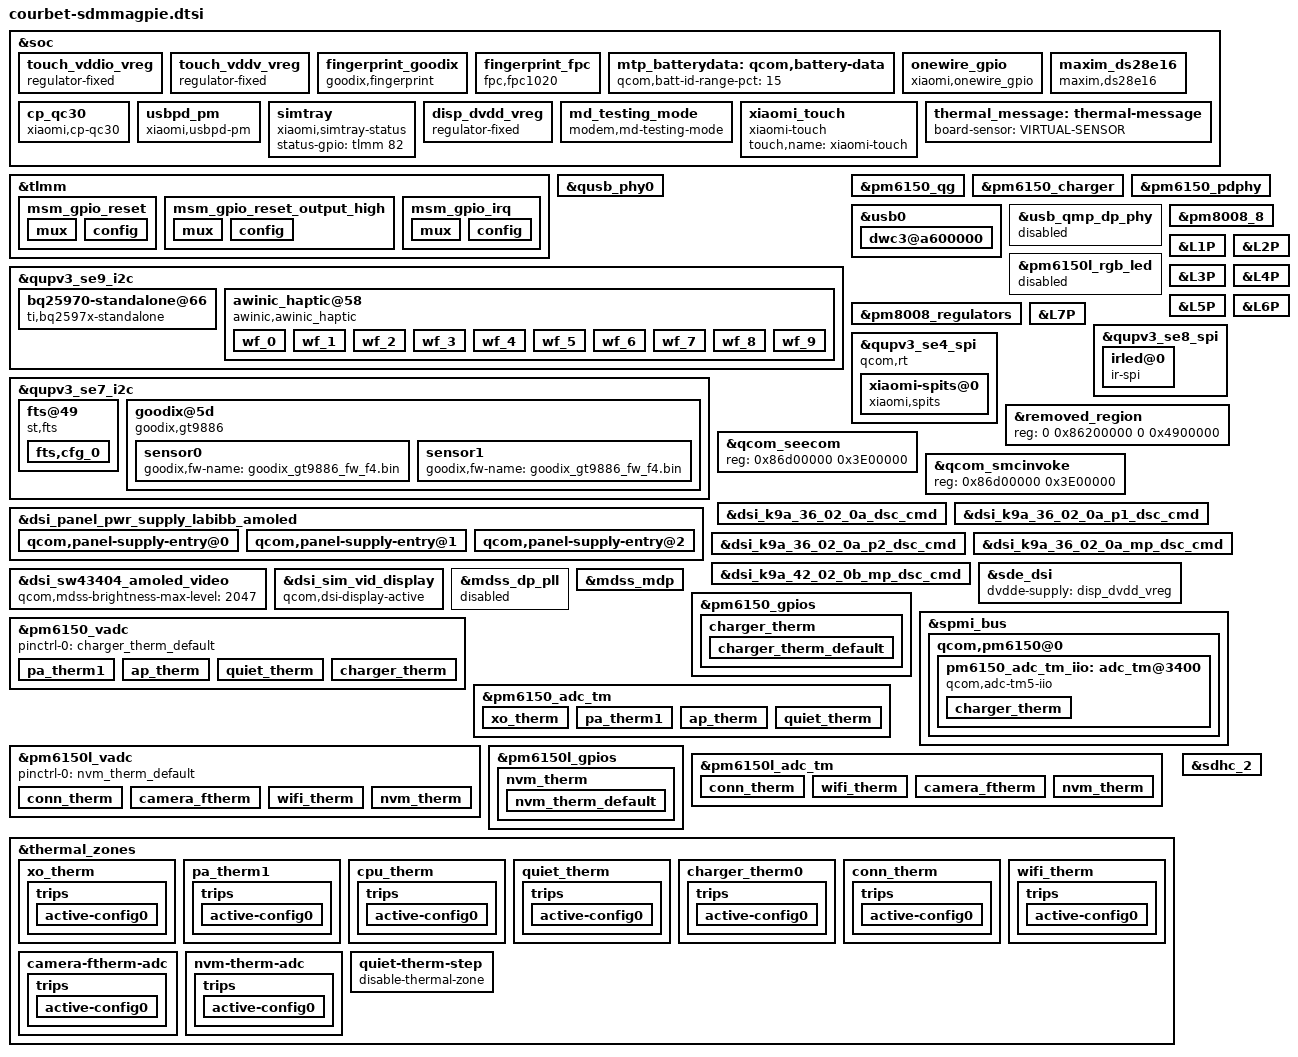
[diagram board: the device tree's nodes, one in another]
/*
this file is for attribution only of aquila
And public attribution of xiaomi platforms(like F3 and so and)
*/

#include "courbet-sdmmagpie-pinctrl.dtsi"
#include "xiaomi-sdmmagpie-common.dtsi"
#include "courbet-sdmmagpie-camera-sensor.dtsi"
&soc {
	touch_vddio_vreg: touch_vddio_vreg {
		compatible = "regulator-fixed";
		regulator-name = "disp_vddio_vreg";
		startup-delay-us = <4000>;
		enable-active-high;
		regulator-boot-off;
		gpio = <&tlmm 72 0>;
		status = "ok";
	};

	touch_vddv_vreg: touch_vddv_vreg {
		compatible = "regulator-fixed";
		regulator-name = "disp_vddio_vreg";
		startup-delay-us = <4000>;
		enable-active-high;
		regulator-boot-off;
		gpio = <&tlmm 21 0>;
		status = "ok";
	};
	fingerprint_goodix {
		compatible = "goodix,fingerprint";
		goodix,gpio-reset = <&tlmm 65 0x0>;
		goodix,gpio-irq = <&tlmm 91 0x0>;
		fp-gpio-pwr = <&tlmm 63 0>;
		status = "ok";
	};

	fingerprint_fpc {
		status = "ok";
		compatible = "fpc,fpc1020";
		interrupt-parent = <&tlmm>;
		interrupts = <91 0x0>;
		fpc,gpio_rst    = <&tlmm 65 0x0>;
		fpc,gpio_irq    = <&tlmm 91 0x0>;
		fpc,gpio_vdd1v8 = <&tlmm 63  0x0>;
		pinctrl-names = "fpc1020_reset_reset",
				"fpc1020_reset_active",
				"fpc1020_irq_active";

		pinctrl-0 = <&msm_gpio_reset>;
		pinctrl-1 = <&msm_gpio_reset_output_high>;
		pinctrl-2 = <&msm_gpio_irq>;
	};


	mtp_batterydata: qcom,battery-data {
		qcom,batt-id-range-pct = <15>;
		#include "qg-batterydata-K9A-cosmx-4250mah.dtsi"
		#include "qg-batterydata-K9A-sunwoda-4250mah.dtsi"
	};

	onewire_gpio: onewire_gpio{
		compatible = "xiaomi,onewire_gpio";
		label = "xm_onewire";
		xiaomi,version = <1>;
		xiaomi,ow_gpio = <&tlmm 94 0x00>;
		mi,onewire-gpio-cfg-addr = <0x03D5E000 0x4>;
		pinctrl-names = "onewire_active", "onewire_sleep";
		pinctrl-0 = <&onewire_gpio_active>;
		pinctrl-1 = <&onewire_gpio_sleep>;
		status = "ok";
	};

	maxim_ds28e16: maxim_ds28e16{
		compatible = "maxim,ds28e16";
		label = "max_ds28e16";
		maxim,version = <1>;
		status = "ok";
	};

	cp_qc30 {
		compatible = "xiaomi,cp-qc30";
		status = "ok";
		mi,qc3-bat-volt-max = <4450>;
		mi,qc3-ffc-bat-volt-max = <4470>;
		mi,qc3-bat-curr-max = <5400>;
		mi,qc3-bus-volt-max = <12000>;
		mi,qc3-bus-curr-max = <2100>;
		mi,support-qc3p5-without-smb;
	};

	usbpd_pm {
		compatible = "xiaomi,usbpd-pm";
		status = "ok";
		mi,pd-bat-volt-max = <4450>;
		mi,pd-ffc-bat-volt-max = <4470>;
		mi,pd-bat-curr-max = <6000>;
		mi,pd-bus-volt-max = <12000>;
		mi,pd-bus-curr-max = <3000>;
		mi,pd-bus-curr-compensate = <200>;
		mi,disable-taper-fcc;
	};

	simtray {
		compatible = "xiaomi,simtray-status";
		status-gpio = <&tlmm 82 0x00>;
	};

	disp_dvdd_vreg: disp_dvdd_vreg {
		compatible = "regulator-fixed";
		regulator-name = "disp_dvdd_vreg";
		startup-delay-us = <4000>;
		enable-active-high;
		regulator-boot-off;
		gpio = <&tlmm 30 0>;
	};

	md_testing_mode {
		compatible = "modem,md-testing-mode";
		status-gpio = <&tlmm 57 0x00>;
		debounce-time = <30>;
		pinctrl-names = "default";
		pinctrl-0 = <&test_mode_irq>;
	};
};

&tlmm {
	/* FP_RESET_N */
	msm_gpio_reset: msm_gpio_reset {
		mux {
			pins = "gpio65";
			function = "gpio";
		};
		config {
			pins = "gpio65";
			drive-strength = <2>;
			bias-disable;
			output-low;
		};
	};
	/* FP_RESET_N, state device active*/
	msm_gpio_reset_output_high: msm_gpio_reset_output_high {
		mux {
			pins = "gpio65";
			function = "gpio";
		};
		config {
			pins = "gpio65";
			drive-strength = <2>;
			bias-disable;
			output-high;
		};
	};
	/* FP_INT_N */
	msm_gpio_irq: msm_gpio_irq {
		mux {
			pins = "gpio91";
			function = "gpio";
		};
		config {
			pins = "gpio91";
			drive-strength = <2>;
			bias-pull-down;
		};
	};
};


&qusb_phy0 {
	mi,no-efuse-tune;

	qcom,qusb-phy-init-seq =
		/* <value reg_offset> */
		<0x23 0x210 /* PWR_CTRL1 */
		0x03 0x04  /* PLL_ANALOG_CONTROLS_TWO */
		0x7c 0x18c /* PLL_CLOCK_INVERTERS */
		0x80 0x2c  /* PLL_CMODE */
		0x0a 0x184 /* PLL_LOCK_DELAY */
		0x19 0xb4  /* PLL_DIGITAL_TIMERS_TWO */
		0x40 0x194 /* PLL_BIAS_CONTROL_1 */
		0x18 0x198 /* PLL_BIAS_CONTROL_2 */
		0x21 0x214 /* PWR_CTRL2 */
		0x08 0x220 /* IMP_CTRL1 */
		0x58 0x224 /* IMP_CTRL2 */
		0x47 0x240 /* TUNE1 */
		0x2b 0x244 /* TUNE2 */
		0xca 0x248 /* TUNE3 */
		0x02 0x24c /* TUNE4 */
		0x03 0x250 /* TUNE5 */
		0x30 0x23c /* CHG_CTRL2 */
		0x22 0x210>; /* PWR_CTRL1 */

	qcom,qusb-phy-host-init-seq =
		/* <value reg_offset> */
		<0x23 0x210 /* PWR_CTRL1 */
		0x03 0x04  /* PLL_ANALOG_CONTROLS_TWO */
		0x7c 0x18c /* PLL_CLOCK_INVERTERS */
		0x80 0x2c  /* PLL_CMODE */
		0x0a 0x184 /* PLL_LOCK_DELAY */
		0x19 0xb4  /* PLL_DIGITAL_TIMERS_TWO */
		0x40 0x194 /* PLL_BIAS_CONTROL_1 */
		0x18 0x198 /* PLL_BIAS_CONTROL_2 */
		0x21 0x214 /* PWR_CTRL2 */
		0x08 0x220 /* IMP_CTRL1 */
		0x58 0x224 /* IMP_CTRL2 */
		0x47 0x240 /* TUNE1 */
		0x2b 0x244 /* TUNE2 */
		0xca 0x248 /* TUNE3 */
		0x02 0x24c /* TUNE4 */
		0x03 0x250 /* TUNE5 */
		0x30 0x23c /* CHG_CTRL2 */
		0x22 0x210>; /* PWR_CTRL1 */
};

&qupv3_se9_i2c {
	status = "ok";
	qcom,clk-freq-out = <400000>;
	qcom,clk-freq-in = <400000>;

	bq25970-standalone@66 {
		compatible = "ti,bq2597x-standalone";
		reg = <0x66>;

		interrupt-parent = <&tlmm>;
		interrupts = <58 0x2002>;
		pinctrl-names = "default";
		pinctrl-0 = <&bq2597x_int_default &bq2597x_int_suspend>;

		mp-sc-vbat-calibrate = <(-10000)>;
		pre-mp-sc-vbat-calibrate = <(-20000)>;
		ti-vbat-calibrate = <(-10000)>;

		//ti,bq2597x,bat-ovp-disable;
		ti,bq2597x,bat-ovp-alarm-disable;
		ti,bq2597x,bat-ocp-disable;
		ti,bq2597x,bat-ocp-alarm-disable;
		ti,bq2597x,bat-ucp-alarm-disable;
		ti,bq2597x,bat-ucp-disable;

		//ti,bq2597x,bus-ovp-alarm-disable;
		//ti,bq2597x,bus-ocp-disable;
		//ti,bq2597x,bus-ocp-alarm-disable;
		ti,bq2597x,bat-therm-disable;
		ti,bq2597x,bus-therm-disable;
		ti,bq2597x,die-therm-disable;

		ti,bq2597x,bat-ovp-threshold = <4525>;
		ti,bq2597x,bat-ovp-alarm-threshold = <4500>;
		//ti,bq2597x,bat-ocp-threshold = <5000>;
		//ti,bq2597x,bat-ocp-alarm-threshold = <4500>;

		ti,bq2597x,bus-ovp-threshold = <12000>;
		ti,bq2597x,bus-ovp-alarm-threshold = <11000>;
		//ti,bq2597x,bus-ocp-threshold = <2200>;
		//ti,bq2597x,bus-ocp-alarm-threshold = <2000>;
		ti,bq2597x,bus-ocp-threshold = <3500>;
		ti,bq2597x,bus-ocp-alarm-threshold = <3200>;

		//ti,bq2597x,bat-ucp-alarm-threshold = <2000>;

		ti,bq2597x,bat-therm-threshold = <0x15>;/*4.1%*/
		ti,bq2597x,bus-therm-threshold = <0x15>;/*4.1%*/
		ti,bq2597x,die-therm-threshold = <145>;

		ti,bq2597x,ac-ovp-threshold = <14>;
		//ti,bq2597x,sense-resistor-mohm = <2>;

		//sc8551,bypass-enable;
	};

	awinic_haptic@58 {
		compatible = "awinic,awinic_haptic";
		reg = <0x5A>;
		aw8622x_i2c_addr = < 0x58 >;
		reset-gpio = <&tlmm 4 0>;
		irq-gpio = <&pm6150l_gpios  10 0>;
		pinctrl-names = "awinic_reset_reset","awinic_reset_active","awinic_interrupt_active";
		pinctrl-0 = <&awinic_gpio_reset>;
		pinctrl-1 = <&awinic_gpio_reset_output_high>;
		pinctrl-2 = <&awinic_gpio_int>;
		/*---------------------aw8624_dts_info---------------------*/
		aw8624_vib_f0_pre = < 2050 >;
		aw8624_vib_f0_cali_percen = < 7 >;
		aw8624_vib_cont_drv_lev = < 106 >;
		aw8624_vib_cont_drv_lvl_ov = < 155 >;
		aw8624_vib_cont_td = < 0xF06C >;
		aw8624_vib_cont_zc_thr = < 0x08F8 >;
		aw8624_vib_cont_num_brk = < 3 >;
		aw8624_vib_f0_coeff = < 260 >; /*Don't modify it*/
		aw8624_vib_duration_time = < 15 60 0 0 0 >;
		aw8624_vib_brake_ram_config = < 1 1 90 60 20 3 1 3 1 1 90 60 30 5 1 3 0 0 50 40 25 0 5 3 >;
		aw8624_vib_brake_cont_config = < 1 1 90 42 20 5 2 2 0 0 0 0 0 0 0 0 0 0 0 0 0 0 0 0 >;
		aw8624_vib_f0_trace_parameter = < 9 5 1 15 >;
		aw8624_vib_bemf_config = < 0 8 3 0xf8 >;
		aw8624_vib_sw_brake = < 0x2c >;
		aw8624_vib_wavseq = < 0 1 1 2 0 0 0 0 0 0 0 0 0 0 0 0 >; /*wavseq1-seq8 0x07-0x0E*/
		aw8624_vib_wavloop = < 0 6 1 15 0 0 0 0 0 0>;/*loop1-mainloog 0x0f-0x13*/
		aw8624_vib_td_brake = < 42720 42720 42720 >; /*level0 level1 level2*/
		aw8624_vib_tset = < 0x11 >;
		aw8624_vib_func_parameter1 = < 1 >;
		aw8624_vib_gain_flag = < 1 >;
		aw8624_vib_r_spare = < 0x68 >;
		aw8624_vib_bstdbg = < 0x30 0xeb 0xd4 0 0 0 >;
		/*---------------------aw8622x_dts_info---------------------*/
		aw8622x_vib_mode = < 0 >; /* mode: RAM mode->0; CONT mode->1 */
		aw8622x_vib_f0_pre = < 2050 >;
		aw8622x_vib_f0_cali_percen = < 7 >;
		aw8622x_vib_cont_drv1_lvl = < 0x7F >;
		aw8622x_vib_cont_drv2_lvl = < 0x3A >;
		aw8622x_vib_cont_brk_time = < 0x06 >;
		aw8622x_vib_cont_tset = < 0x06 >;
		aw8622x_vib_cont_bemf_set = < 0x02 >;
		aw8622x_vib_cont_drv_width = < 0x56 >;
		aw8622x_vib_cont_wait_num = < 0x06 >;
		aw8622x_vib_cont_brk_gain = < 0x08 >;
		aw8622x_vib_cont_drv1_time = < 0x08 >;
		aw8622x_vib_cont_drv2_time = < 0x14 >;
		aw8622x_vib_cont_track_margin = < 0x0F >;
		aw8622x_vib_sine_array = < 0x05 0xB2 0xFF 0xEF >; /* SIN_H SIN_L COS_H COS_L*/
		aw8622x_vib_d2s_gain = < 0x05 >;
		aw8622x_vib_prctmode = < 0x2D 0x3E 0x3F >;
		/*---------------------common_dts_info---------------------*/
		vib_effect_id_boundary = < 10 >;
		vib_effect_max = < 170 >;
		vib_rtp_time = < 20 20 20 20 20 20 20 20 20 30
				 40 50 60 70 80 90 100 110 120 130
				 140 150 160 170 180 190 200 210 220 230
				 240 250 260 270 280 290 300 310 320 330
				 20 20 20 20 20 20 20 20 20 20
				 20 20 20 20 20 20 20 20 20 20
				 20 20 20 20 20 20 20 20 20 20
				 20 20 20 20 20 20 20 20 20 20
				 20 20 20 20 20 20 20 20 20 20
				 20 20 20 20 20 20 20 20 20 20
				 20 20 20 20 20 20 20 20 20 20
				 20 20 20 20 20 20 20 20 20 20
				 20 20 20 20 20 20 20 20 20 20
				 20 20 20 20 20 20 20 20 20 20
				 20 20 20 20 20 20 20 20 20 20
				 20 20 20 20 20 20 20 20 20 20
				 20 20 20 20 20 20 20 20 20 20
				 20 20 20 20 20 >;
		status = "okay";
		wf_0 {
			/*CLICK*/
			qcom,effect-id = <0>;
			qcom,wf-vmax-mv = <3600>;
			qcom,wf-pattern = [3e 3e];
			qcom,wf-brake-pattern = [02 01 00 00];
			qcom,wf-play-rate-us = <20000>;
		};
		wf_1 {
			/*DOUBLE CLICK*/
			qcom,effect-id = <1>;
			qcom,wf-vmax-mv = <3600>;
			qcom,wf-pattern = [7e 3e];
			qcom,wf-brake-pattern = [03 01 00 00];
			qcom,wf-play-rate-us = <20000>;
		};
		wf_2 {
			/*TICK*/
			qcom,effect-id = <2>;
			qcom,wf-vmax-mv = <3600>;
			qcom,wf-pattern = [7e 3e];
			qcom,wf-brake-pattern = [02 01 00 00];
			qcom,wf-play-rate-us = <20000>;
		};
		wf_3 {
			/*THUD*/
			qcom,effect-id = <3>;
			qcom,wf-vmax-mv = <3600>;
			qcom,wf-pattern = [3e 3e];
			qcom,wf-brake-pattern = [02 01 00 00];
			qcom,wf-play-rate-us = <20000>;
		};
		wf_4 {
			/*POP*/
			qcom,effect-id = <4>;
			qcom,wf-vmax-mv = <3600>;
			qcom,wf-pattern = [3e 3e];
			qcom,wf-brake-pattern = [02 01 00 00];
			qcom,wf-play-rate-us = <28000>;
		};
		wf_5 {
			/*HEAVY CLICK*/
			qcom,effect-id = <5>;
			qcom,wf-vmax-mv = <3600>;
			qcom,wf-pattern = [7e 7e 7e];
			qcom,wf-brake-pattern = [03 03 01 00];
			qcom,wf-play-rate-us = <20000>;
		};
		wf_6 {
			/*id 6*/
			qcom,effect-id = <6>;
			qcom,wf-vmax-mv = <3600>;
			qcom,wf-pattern = [3e 3e];
			qcom,wf-brake-pattern = [02 01 00 00];
			qcom,wf-play-rate-us = <20000>;
		};
		wf_7 {
			/*id 7*/
			qcom,effect-id = <7>;
			qcom,wf-vmax-mv = <3600>;
			qcom,wf-pattern = [3e 3e];
			qcom,wf-brake-pattern = [02 01 00 00];
			qcom,wf-play-rate-us = <20000>;
		};
		wf_8 {
			/*id 8*/
			qcom,effect-id = <8>;
			qcom,wf-vmax-mv = <3600>;
			qcom,wf-pattern = [3e 3e];
			qcom,wf-brake-pattern = [02 01 00 00];
			qcom,wf-play-rate-us = <20000>;
		};
		wf_9 {
			/*id 9*/
			qcom,effect-id = <9>;
			qcom,wf-vmax-mv = <3600>;
			qcom,wf-pattern = [3e 3e];
			qcom,wf-brake-pattern = [02 01 00 00];
			qcom,wf-play-rate-us = <20000>;
		};
	};
	/* AWINIC AW8624 Haptic End */
};

&pm6150_qg {
	qcom,battery-data = <&mtp_batterydata>;
	qcom,vbatt-cutoff-mv = <3400>;
	qcom,vbatt-low-mv = <3500>;
	qcom,vbatt-low-cold-mv = <3800>;
	qcom,vbatt-empty-mv = <3100>;
	qcom,vbatt-empty-cold-mv = <3000>;
	qcom,s3-entry-fifo-length = <2>;
	qcom,s3-entry-ibat-ua = <25000>;
	qcom,s3-exit-ibat-ua = <45000>;
	qcom,qg-iterm-ma = <300>;
	qcom,hold-soc-while-full;
	qcom,linearize-soc;
	qcom,cl-feedback-on;
	qcom,shutdown-soc-threshold = <10>;
	qcom,qg-ext-sns;
	mi,software-optimize-ffc-qg-iterm;
	qcom,shutdown-delay-enable;
	qcom,tcss-enable;
	qcom,tcss-entry-soc = <90>;
	qcom,bass-enable;
	qcom,disable-hold-full;

	qcom,soc_decimal_rate = <
		0  32
		10 30
		20 28
		30 28
		40 28
		50 28
		60 28
		70 28
		80 28
		90 26
		95 10
		99 5>;
};

&pm6150_charger {
	io-channels = <&pm6150_vadc ADC_USB_IN_V_16>,
		      <&pm6150_vadc ADC_USB_IN_I>,
		      <&pm6150_vadc ADC_CHG_TEMP>,
		      <&pm6150_vadc ADC_DIE_TEMP>,
		      <&pm6150l_vadc ADC_AMUX_THM1_PU2>,
		      <&pm6150_vadc ADC_SBUx>,
		      <&pm6150_vadc ADC_VPH_PWR>;
	io-channel-names = "usb_in_voltage",
			   "usb_in_current",
			   "chg_temp",
			   "die_temp",
			   "conn_temp",
			   "sbux_res",
			   "vph_voltage";
	qcom,battery-data = <&mtp_batterydata>;
	qcom,usb-icl-ua = <3000000>;
	mi,ffc-low-tbat = <150>;
	mi,ffc-high-tbat = <480>;
	qcom,fcc-max-ua = <6000000>;
	mi,fcc-batt-unverify-ua = <2000000>;
	qcom,fv-max-uv = <4480000>;
	qcom,auto-recharge-soc = <99>;
	qcom,chg-term-src = <1>;
	qcom,chg-term-current-ma = <(-200)>;
	qcom,sec-charger-config = <0>;

	qcom,thermal-mitigation = <5900000 5000000 4500000 4000000 3500000 3000000 2900000
				   2800000 2600000 2400000 2200000 2000000 1800000 1500000
				   1000000 500000>;
	qcom,thermal-mitigation-icl
				 = <3000000 3000000 3000000 2400000 2200000 2100000 2000000
				   2000000 2000000 1900000 1800000 1600000 1500000 1300000
				   1000000 750000>;
	qcom,thermal-mitigation-dcp
				= <1800000 1800000 1800000 1800000 1800000 1800000 1800000
				   1800000 1800000 1700000 1600000 1400000 1200000 1100000
				   1100000 1000000>;
	qcom,thermal-mitigation-qc2
				= <1500000 1500000 1500000 1500000 1450000 1400000 1350000
				   1300000 1150000 1100000 1000000 900000 850000 750000
				   650000 500000>;
	qcom,thermal-fcc-qc3-normal
				= <6000000 5000000 4500000 4000000 3500000 3000000 2900000
				   2800000 2700000 2600000 2400000 2200000 2000000 2000000
				   750000 700000>;
	qcom,thermal-fcc-qc3-cp
				= <6000000 5000000 4500000 4000000 3500000 3300000 3200000
				   3100000 3000000 2800000 2600000 2400000 2200000 2000000
				   2000000 200000>;
	qcom,thermal-mitigation-pd-base
				= <6000000 5000000 4500000 4000000 3400000 3300000 3200000
				   3100000 3000000 2800000 2600000 2400000 2200000 2000000
				   1000000 700000>;
	qcom,thermal-fcc-pps-cp
				= <6000000 5700000 5400000 5000000 4700000 4400000 4100000
				   3800000 3500000 3200000 2800000 2400000 2000000 1500000
				   1000000 700000>;
	dpdm-supply = <&qusb_phy0>;
	qcom,reg-dump-enable;
	qcom,sw-jeita-enable;
	qcom,step-charging-enable;
	qcom,distinguish-qc-class-ab;
	qcom,lpd-disable;
	qcom,usbpd-phandle = <&pm6150_pdphy>;
	qcom,support-conn-therm;
	qcom,disable-suspend-on-collapse;

	mi,use-bq-pump;
	mi,support-ffc;
	mi,early-status-report;
	mi,support-qc3p5-without-smb;
	mi,pps-thermal-setting-disable;
	mi,fcc-calibrate-ua = <(-50000)>;
	mi,reverse_boost-wa;
	mi,rara-cc2-toggle-wa;

	uart-en-gpio = <&tlmm 33 0>;
	pinctrl-names = "default";
	pinctrl-0 = <&uart_en_default>;
};

&pm6150_pdphy {
	mi,non-qcom-pps-ctrl;
	mi,pd_curr_limit = <1>;
	mi,pd_max_curr_limit = <4000000>;
	mi,limit_pd_unverified_pps_vbus = <1>;
	mi,pd_unverified_pps_max_vbus_limit = <9500000>;
	mi,smart-interchg-enable;
};

&usb0 {
	dwc3@a600000 {
		usb-phy = <&qusb_phy0>, <&usb_nop_phy>;
		maximum-speed = "high-speed";
	};
};

&usb_qmp_dp_phy {
	status = "disabled";
};


&pm6150l_rgb_led {
	status = "disabled";
};


&qupv3_se7_i2c{
	status = "ok";
	fts@49 {
		compatible = "st,fts";
		reg = <0x49>;
		interrupt-parent = <&tlmm>;
		interrupts = <9 0x2008>;
		pinctrl-names = "pmx_ts_active", "pmx_ts_suspend";
		pinctrl-0 = <&ts_active>;
		pinctrl-1 = <&ts_int_suspend &ts_reset_suspend>;
		vdd-supply = <&touch_vddio_vreg>;
		avdd-supply = <&pm6150l_l6>;
		fts,pwr-reg-name = "avdd";
		fts,bus-reg-name = "vdd";
		fts,irq-gpio = <&tlmm 9 0x2008>;
		fts,irq-gpio-name = "fts_irq";
		fts,reset-gpio-enable;
		fts,reset-gpio = <&tlmm 8 0x00>;
		fts,reset-gpio-name = "fts_rst";
		fts,irq-flags = <0x2008>; /* IRQF_ONESHOT | IRQF_TRIGGER_LOW */
		fts,x-max = <1080>;
		fts,y-max = <2340>;
		fts,default-fw-name = "st_fts_f4l.ftb";
		fts,config-array-size = <1>;
		fts,dump-click-count;
		fts,touch-up-threshold-min = <40>;
		fts,touch-up-threshold-max = <120>;
		fts,touch-up-threshold-def = <80>;
		fts,touch-tolerance-min = <5>;
		fts,touch-tolerance-max = <35>;
		fts,touch-tolerance-def = <25>;
		/*edge filter rects in gamemode*/
		fts,cornerfilter-area-step1 = <100>;
		fts,cornerfilter-area-step2 = <170>;
		fts,cornerfilter-area-step3 = <250>;
		fts,touch-deadzone-filter-ver = <2 0 0 0 0 0 0 0
									    2 1 0 0 0 0 0 0
									    2 2 0 0 5 2339 0 0
									    2 3 1074 0 1079 2339 0 0>;
		fts,touch-deadzone-filter-hor = <2 0 0 0 1079 5 0 0
									    2 1 0 2334 1079 2339 0 0
									    2 2 0 0 5 2339 0 0
									    2 3 1074 0 1079 2339 0 0>;
		fts,touch-edgezone-filter-ver = <1 0 0 0 0 0 0 0
									    1 1 0 0 0 0 0 0
									    1 2 0 0 40 2339 0 0
									    1 3 1039 0 1079 2339 0 0>;
		fts,touch-edgezone-filter-hor = <1 0 0 0 1079 40 0 0
									    1 1 0 2299 1079 2339 0 0
									    1 2 0 0 40 2339 0 0
									    1 3 1039 0 1079 2339 0 0>;
		fts,touch-cornerzone-filter-ver = <0 0 0 0 0 0 0 0
									    0 1 0 0 0 0 0 0
									    0 2 0 2039 150 2339 0 0
									    0 3 929 2039 1079 2339 0 0>;
		fts,touch-cornerzone-filter-hor1 = <0 0 0 0 170 170 0 0
									    0 1 0 0 0 0 0 0
									    0 2 0 2169 170 2339 0 0
									    0 3 0 0 0 0 0 0>;
		fts,touch-cornerzone-filter-hor2 = <0 0 0 0 0 0 0 0
									    0 1 909 0 1079 170 0 0
									    0 2 0 0 0 0 0 0
									    0 3 909 2169 1079 2339 0 0>;
		fts,touch-idletime-min = <0>;
		fts,touch-idletime-max = <12750>;
		fts,touch-idletime-def = <12450>;
		fts,cfg_0 {
			fts,tp-vendor = <0x51>;
			fts,fw-name = "st_fts_f4l.ftb";
			fts,limit-name = "stm_fts_production_limits.csv";
			fts,clicknum-file-name = "fts+sdc";
		};
	};
	goodix@5d {
		compatible = "goodix,gt9886";
		reg = <0x5d>;
		status = "ok";
		interrupt-parent = <&tlmm>;
		interrupts = <9 0x2800>;
		vtouch-supply = <&pm6150l_l6>;
		iotouch-supply = <&touch_vddio_vreg>;
		vtouch-load = <600000>;
		pinctrl-names = "pmx_ts_active","pmx_ts_suspend";
		pinctrl-0 = <&tp_active>;
		pinctrl-1 = <&tp_int_suspend &tp_reset_suspend>;
		goodix,reset-gpio = <&tlmm 8 0x0>;
		goodix,irq-gpio = <&tlmm 9 0x2800>;
		goodix,irq-flags = <2>; /* 1:trigger rising, 2:trigger falling;*/
		goodix,panel-max-id = <10>;
		goodix,panel-max-x = <1079>;
		goodix,panel-max-y = <2339>;
		goodix,panel-max-w = <127>;
		goodix,panel-max-p = <127>;
		goodix,panel-max-fod = <127>;
	/*	goodix,panel-key-map = <158 172 217>; */ /*KEY_BACK, KEY_HOMEPAGE, KEY_SEARCH*/
		goodix,power-on-delay-us = <300000>; /*300ms*/
		goodix,power-off-delay-us = <5000>;
		goodix,cfg-name = "goodix_gt9886_cfg_f4.bin";
		normal-cfg = [
				];
	/*	goodix,swap-axis; */
	/*	goodix,pen-enable; */
	/*	goodix,key-of-pen = <331 332>; */ /*BTN_STYLUS, BTN_STYLUS2*/
		goodix,touch-deadzone-filter-ver = <2 0 0 0 0 0 0 0
									    2 1 0 0 0 0 0 0
									    2 2 0 0 5 2339 0 0
									    2 3 1074 0 1079 2339 0 0>;
		goodix,touch-deadzone-filter-hor = <2 0 0 0 1079 5 0 0
									    2 1 0 2334 1079 2339 0 0
									    2 2 0 0 5 2339 0 0
									    2 3 1074 0 1079 2339 0 0>;
		goodix,touch-edgezone-filter-ver = <1 0 0 0 0 0 0 0
									    1 1 0 0 0 0 0 0
									    1 2 0 0 40 2339 0 0
									    1 3 1039 0 1079 2339 0 0>;
		goodix,touch-edgezone-filter-hor = <1 0 0 0 1079 40 0 0
									    1 1 0 2299 1079 2339 0 0
									    1 2 0 0 40 2339 0 0
									    1 3 1039 0 1079 2339 0 0>;
		goodix,touch-cornerzone-filter-ver = <0 0 0 0 0 0 0 0
									    0 1 0 0 0 0 0 0
									    0 2 0 2039 150 2339 0 0
									    0 3 929 2039 1079 2339 0 0>;
		goodix,touch-cornerzone-filter-hor1 = <0 0 0 0 170 170 0 0
									    0 1 0 0 0 0 0 0
									    0 2 0 2169 170 2339 0 0
									    0 3 0 0 0 0 0 0>;
		goodix,touch-cornerzone-filter-hor2 = <0 0 0 0 0 0 0 0
									    0 1 909 0 1079 170 0 0
									    0 2 0 0 0 0 0 0
									    0 3 909 2169 1079 2339 0 0>;
		goodix,edge-filter-corner-size = /bits/ 16 <100 170 250>;
		sensor0 {
				goodix,fw-name = "goodix_gt9886_fw_f4.bin";
				/*goodix,x2x;*/
				/*goodix,y2y;*/
		};
		sensor1 {
				goodix,fw-name = "goodix_gt9886_fw_f4.bin";
		};
	};
        #include "pm8008.dtsi"
};

&pm8008_8 {
	/* PM8008 IRQ STAT */
	interrupt-parent = <&tlmm>;
	interrupts = <93 IRQ_TYPE_EDGE_RISING>;

	pinctrl-names = "default";
	pinctrl-0 = <&pm8008_active &pm8008_interrupt>;
};

&pm8008_regulators {
	vdd_l1_l2-supply = <&S8C>;
	vdd_l3_l4-supply = <&BOB>;
	vdd_l5-supply = <&S5A>;
	vdd_l6-supply = <&BOB>;
	vdd_l7-supply = <&BOB>;
};

&L1P {
	regulator-max-microvolt = <1050000>;
	qcom,min-dropout-voltage = <192000>;
};

&L2P {
	regulator-max-microvolt = <1200000>;
	qcom,min-dropout-voltage = <192000>;
};

&L3P {
	regulator-max-microvolt = <2800000>;
	qcom,min-dropout-voltage = <128000>;
};

&L4P {
	regulator-max-microvolt = <2804000>;
	qcom,min-dropout-voltage = <96000>;
};

&L5P {
	regulator-max-microvolt = <1800000>;
	qcom,min-dropout-voltage = <200000>;
};

&L6P {
	regulator-max-microvolt = <2800000>;
	/* Reduced the headroom by 16mV for AHC */
	qcom,min-dropout-voltage = <56000>;
};

&L7P {
	regulator-max-microvolt = <2700000>;
	qcom,min-dropout-voltage = <120000>;
};

&qupv3_se8_spi {
	status = "ok";
	irled@0 {
		compatible = "ir-spi";
		reg = <0x0>;
		status = "ok";
		spi-max-frequency = <19200000>;
	};
};

&qupv3_se4_spi {
	status = "ok";
	qcom,rt;

	xiaomi-spits@0 {
		status = "ok";
		compatible = "xiaomi,spits";
		reg = <0>;
		spi-max-frequency = <8000000>;
		goodix,avdd-name = "avdd";
		avdd-supply = <&touch_vddv_vreg>;
		goodix,pmavdd-name = "pmavdd";
		pmavdd-supply = <&pm6150l_l11>;
		goodix,iovdd-name = "iovdd";
		iovdd-supply = <&touch_vddio_vreg>;
		goodix,reset-gpio = <&tlmm 8 0x0>;
		goodix,irq-gpio = <&tlmm 9 0x2800>;
		goodix,irq-flags = <2>; /* 1:trigger rising, 2:trigger falling;*/
		goodix,panel-max-x = <1079>;
		goodix,panel-max-y = <2399>;
		goodix,panel-max-w = <255>;
		goodix,panel-max-p = <255>; /* max pressure that pen device supported */
		/* goodix,pen-enable; */ /* support active stylus device*/

		pinctrl-names = "pmx_ts_active", "pmx_ts_suspend", "pmx_ts_release";
		pinctrl-0 = <&ts_active>;
		pinctrl-1 = <&ts_int_suspend &ts_reset_suspend>;
		pinctrl-2 = <&ts_release>;
		vdd-supply = <&pm6150l_l11>;
		vcc_i2c-supply = <&touch_vddio_vreg>;
		focaltech,reset-gpio = <&tlmm 8 0x00>;
		focaltech,irq-gpio = <&tlmm 9 0x2008>;
		focaltech,max-touch-number = <10>;
		focaltech,display-coords = <0 0 1080 2400>;
	};
};

&soc {
	xiaomi_touch {
		compatible = "xiaomi-touch";
		status = "ok";
		touch,name = "xiaomi-touch";
	};
	thermal_message: thermal-message {
		board-sensor = "VIRTUAL-SENSOR";
	};
};

/* Enlarge TZ memory size to 62M */
&removed_region {
	reg = <0 0x86200000 0 0x4900000>;
};

&qcom_seecom {
	reg = <0x86d00000 0x3E00000>;
};

&qcom_smcinvoke {
	reg = <0x86d00000 0x3E00000>;
};


&dsi_panel_pwr_supply_labibb_amoled {

	qcom,panel-supply-entry@0 {
		reg = <0>;
		qcom,supply-name = "vddio";
		qcom,supply-min-voltage = <1880000>;
		qcom,supply-max-voltage = <1880000>;
		qcom,supply-enable-load = <32000>;
		qcom,supply-disable-load = <80>;
		qcom,supply-pre-off-sleep = <20>;
		qcom,supply-post-off-sleep = <100>;
	};

	qcom,panel-supply-entry@1 {
		reg = <1>;
		qcom,supply-name = "dvdde";
		qcom,supply-min-voltage = <1200000>;
		qcom,supply-max-voltage = <1200000>;
		qcom,supply-enable-load = <32000>;
		qcom,supply-disable-load = <80>;
		qcom,supply-pre-off-sleep = <10>;
	};

	qcom,panel-supply-entry@2 {
		reg = <2>;
		qcom,supply-name = "vdda-3p3";
		qcom,supply-min-voltage = <3000000>;
		qcom,supply-max-voltage = <3000000>;
		qcom,supply-enable-load = <13200>;
		qcom,supply-disable-load = <80>;
		qcom,supply-pre-off-sleep = <10>;
	};
};

&dsi_k9a_36_02_0a_dsc_cmd {
	qcom,panel-supply-entries = <&dsi_panel_pwr_supply_labibb_amoled>;
	qcom,mdss-dsi-bl-pmic-control-type = "bl_ctrl_dcs";
	qcom,mdss-dsi-bl-min-level = <1>;
	qcom,mdss-dsi-bl-max-level = <2047>;
	qcom,mdss-brightness-max-level = <2047>;
	qcom,mdss-dsi-mode-sel-gpio-state = "single_port";
	//qcom,platform-en-gpio = <&tlmm 30 0>;
	qcom,platform-te-gpio = <&tlmm 10 0>;
	qcom,platform-reset-gpio = <&pm6150l_gpios 9 0>;
};

&dsi_k9a_36_02_0a_p1_dsc_cmd {
	qcom,panel-supply-entries = <&dsi_panel_pwr_supply_labibb_amoled>;
	qcom,mdss-dsi-bl-pmic-control-type = "bl_ctrl_dcs";
	qcom,mdss-dsi-bl-min-level = <1>;
	qcom,mdss-dsi-bl-max-level = <2047>;
	qcom,mdss-brightness-max-level = <2047>;
	qcom,mdss-dsi-mode-sel-gpio-state = "single_port";
	//qcom,platform-en-gpio = <&tlmm 30 0>;
	qcom,platform-te-gpio = <&tlmm 10 0>;
	qcom,platform-reset-gpio = <&pm6150l_gpios 9 0>;
};

&dsi_k9a_36_02_0a_p2_dsc_cmd {
	qcom,panel-supply-entries = <&dsi_panel_pwr_supply_labibb_amoled>;
	qcom,mdss-dsi-bl-pmic-control-type = "bl_ctrl_dcs";
	qcom,mdss-dsi-bl-min-level = <1>;
	qcom,mdss-dsi-bl-max-level = <2047>;
	qcom,mdss-brightness-max-level = <2047>;
	qcom,mdss-dsi-mode-sel-gpio-state = "single_port";
	//qcom,platform-en-gpio = <&tlmm 30 0>;
	qcom,platform-te-gpio = <&tlmm 10 0>;
	qcom,platform-reset-gpio = <&pm6150l_gpios 9 0>;
};

&dsi_k9a_36_02_0a_mp_dsc_cmd {
	qcom,panel-supply-entries = <&dsi_panel_pwr_supply_labibb_amoled>;
	qcom,mdss-dsi-bl-pmic-control-type = "bl_ctrl_dcs";
	qcom,mdss-dsi-bl-min-level = <1>;
	qcom,mdss-dsi-bl-max-level = <2047>;
	qcom,mdss-brightness-max-level = <2047>;
	qcom,mdss-dsi-mode-sel-gpio-state = "single_port";
	//qcom,platform-en-gpio = <&tlmm 30 0>;
	qcom,platform-te-gpio = <&tlmm 10 0>;
	qcom,platform-reset-gpio = <&pm6150l_gpios 9 0>;
};

&dsi_k9a_42_02_0b_mp_dsc_cmd {
	qcom,panel-supply-entries = <&dsi_panel_pwr_supply_labibb_amoled>;
	qcom,mdss-dsi-bl-pmic-control-type = "bl_ctrl_dcs";
	qcom,mdss-dsi-bl-min-level = <1>;
	qcom,mdss-dsi-bl-max-level = <2047>;
	qcom,mdss-brightness-max-level = <2047>;
	qcom,mdss-dsi-mode-sel-gpio-state = "single_port";
	//qcom,platform-en-gpio = <&tlmm 30 0>;
	qcom,platform-te-gpio = <&tlmm 10 0>;
	qcom,platform-reset-gpio = <&pm6150l_gpios 9 0>;
};

&sde_dsi {
	dvdde-supply = <&disp_dvdd_vreg>;
};

&dsi_sw43404_amoled_video {
	qcom,mdss-brightness-max-level = <2047>;
};

&dsi_sim_vid_display {
	qcom,dsi-display-active;
};

&mdss_dp_pll {
	status = "disabled";
};

&mdss_mdp {
	connectors = <&sde_rscc &sde_wb &sde_dsi &sde_dsi1>;
};

&pm6150_gpios {
	charger_therm {
		charger_therm_default: charger_therm_default {
			pins = "gpio1";
			bias-high-impedance;
		};
	};
};

&pm6150_vadc {
	pinctrl-names = "default";
	pinctrl-0 = <&charger_therm_default>;

	pa_therm1 {
		reg = <ADC_AMUX_THM2_PU2>;
		label = "pa_therm1";
		qcom,ratiometric;
		qcom,hw-settle-time = <200>;
		qcom,pre-scaling = <1 1>;
	};

	ap_therm {
		reg = <ADC_AMUX_THM3_PU2>;
		label = "ap_therm";
		qcom,ratiometric;
		qcom,hw-settle-time = <200>;
		qcom,pre-scaling = <1 1>;
	};

	quiet_therm {
		reg = <ADC_AMUX_THM4_PU2>;
		label = "quiet_therm";
		qcom,ratiometric;
		qcom,hw-settle-time = <200>;
		qcom,pre-scaling = <1 1>;
	};

	charger_therm {
		reg = <ADC_GPIO1_PU2>;
		label = "charger_therm";
		qcom,ratiometric;
		qcom,hw-settle-time = <200>;
		qcom,pre-scaling = <1 1>;
	};
};

&spmi_bus {
        qcom,pm6150@0 {
                pm6150_adc_tm_iio: adc_tm@3400 {
                        compatible = "qcom,adc-tm5-iio";
                        reg = <0x3400 0x100>;
                        #thermal-sensor-cells = <1>;
                        #address-cells = <1>;
                        #size-cells = <0>;
                        io-channels = <&pm6150_vadc ADC_GPIO1_PU2>;

                        charger_therm {
                                reg = <ADC_GPIO1_PU2>;
                                qcom,ratiometric;
                                qcom,hw-settle-time = <200>;
                        };
                };
        };
};

&pm6150_adc_tm {
	io-channels =	<&pm6150_vadc ADC_XO_THERM_PU2>,
			<&pm6150_vadc ADC_AMUX_THM2_PU2>,
			<&pm6150_vadc ADC_AMUX_THM3_PU2>,
			<&pm6150_vadc ADC_AMUX_THM4_PU2>;
	/* Channel nodes */
	xo_therm {
		reg = <ADC_XO_THERM_PU2>;
		qcom,ratiometric;
		qcom,hw-settle-time = <200>;
	};

	pa_therm1 {
		reg = <ADC_AMUX_THM2_PU2>;
		qcom,ratiometric;
		qcom,hw-settle-time = <200>;
	};

	ap_therm {
		reg = <ADC_AMUX_THM3_PU2>;
		qcom,ratiometric;
		qcom,hw-settle-time = <200>;
	};

	quiet_therm {
		reg = <ADC_AMUX_THM4_PU2>;
		qcom,ratiometric;
		qcom,hw-settle-time = <200>;
	};
};

&pm6150l_vadc {
        pinctrl-names = "default";
        pinctrl-0 = <&nvm_therm_default>;

	conn_therm {
		reg = <ADC_AMUX_THM1_PU2>;
		label = "conn_therm";
		qcom,ratiometric;
		qcom,hw-settle-time = <200>;
		qcom,pre-scaling = <1 1>;
	};

	camera_ftherm {
		reg = <ADC_AMUX_THM3_PU2>;
		label = "camera_ftherm";
		qcom,ratiometric;
		qcom,hw-settle-time = <200>;
		qcom,pre-scaling = <1 1>;
	};

        wifi_therm {
                reg = <ADC_AMUX_THM2_PU2>;
                label = "wifi_therm";
                qcom,ratiometric;
                qcom,hw-settle-time = <200>;
                qcom,pre-scaling = <1 1>;
        };

	nvm_therm {
		reg = <ADC_GPIO4_PU2>;
		label = "nvm_therm";
		qcom,ratiometric;
		qcom,hw-settle-time = <200>;
		qcom,pre-scaling = <1 1>;
	};

};

&pm6150l_gpios {
	nvm_therm {
		nvm_therm_default: nvm_therm_default {
			pins = "gpio4";
			bias-high-impedance;
		};
	};
};

&pm6150l_adc_tm {
	io-channels = <&pm6150l_vadc ADC_AMUX_THM1_PU2>,
			<&pm6150l_vadc ADC_AMUX_THM2_PU2>,
			<&pm6150l_vadc ADC_AMUX_THM3_PU2>,
			<&pm6150l_vadc ADC_GPIO4_PU2>;

	/* Channel nodes */
	conn_therm {
		reg = <ADC_AMUX_THM1_PU2>;
		qcom,ratiometric;
		qcom,hw-settle-time = <200>;
	};

        wifi_therm {
                reg = <ADC_AMUX_THM2_PU2>;
                qcom,ratiometric;
                qcom,hw-settle-time = <200>;
        };

	camera_ftherm {
		reg = <ADC_AMUX_THM3_PU2>;
		qcom,ratiometric;
		qcom,hw-settle-time = <200>;
	};

	nvm_therm {
		reg = <ADC_GPIO4_PU2>;
		qcom,ratiometric;
		qcom,hw-settle-time = <200>;
	};
};

&thermal_zones {
	xo_therm {
		polling-delay-passive = <0>;
		polling-delay = <0>;
		thermal-governor = "user_space";
		thermal-sensors = <&pm6150_adc_tm ADC_XO_THERM_PU2>;
		trips {
			active-config0 {
				temperature = <125000>;
				hysteresis = <1000>;
				type = "passive";
			};
		};
	};

	pa_therm1 {
		polling-delay-passive = <0>;
		polling-delay = <0>;
		thermal-governor = "user_space";
		thermal-sensors = <&pm6150_adc_tm ADC_AMUX_THM2_PU2>;
		trips {
			active-config0 {
				temperature = <125000>;
				hysteresis = <1000>;
				type = "passive";
			};
		};
	};

	cpu_therm {
		polling-delay-passive = <0>;
		polling-delay = <0>;
		thermal-governor = "user_space";
		thermal-sensors = <&pm6150_adc_tm ADC_AMUX_THM3_PU2>;
		trips {
			active-config0 {
				temperature = <125000>;
				hysteresis = <1000>;
				type = "passive";
			};
		};
	};

	quiet_therm {
		polling-delay-passive = <0>;
		polling-delay = <0>;
		thermal-governor = "user_space";
		thermal-sensors = <&pm6150_adc_tm ADC_AMUX_THM4_PU2>;
		trips {
			active-config0 {
				temperature = <125000>;
				hysteresis = <1000>;
				type = "passive";
			};
		};
	};

	charger_therm0 {
		polling-delay-passive = <0>;
		polling-delay = <0>;
		thermal-governor = "user_space";
		thermal-sensors = <&pm6150_adc_tm_iio ADC_GPIO1_PU2>;
		trips {
			active-config0 {
				temperature = <125000>;
				hysteresis = <1000>;
				type = "passive";
			};
		};
	};

	conn_therm {
		polling-delay-passive = <0>;
		polling-delay = <0>;
		thermal-governor = "user_space";
		thermal-sensors = <&pm6150l_adc_tm ADC_AMUX_THM1_PU2>;
		trips {
			active-config0 {
				temperature = <125000>;
				hysteresis = <1000>;
				type = "passive";
			};
		};
	};

	wifi_therm {
		polling-delay-passive = <0>;
		polling-delay = <0>;
		thermal-governor = "user_space";
		thermal-sensors = <&pm6150l_adc_tm ADC_AMUX_THM2_PU2>;
		trips {
			active-config0 {
				temperature = <125000>;
				hysteresis = <1000>;
				type = "passive";
			};
		};
	};

	camera-ftherm-adc {
		polling-delay-passive = <0>;
		polling-delay = <0>;
		thermal-governor = "user_space";
		thermal-sensors = <&pm6150l_adc_tm ADC_AMUX_THM3_PU2>;
		trips {
			active-config0 {
				temperature = <125000>;
				hysteresis = <1000>;
				type = "passive";
			};
		};
	};

	nvm-therm-adc {
		polling-delay-passive = <0>;
		polling-delay = <0>;
		thermal-governor = "user_space";
		thermal-sensors = <&pm6150l_adc_tm ADC_GPIO4_PU2>;
		trips {
			active-config0 {
				temperature = <125000>;
				hysteresis = <1000>;
				type = "passive";
			};
		};
	};

	quiet-therm-step {
		disable-thermal-zone;
	};
};

&sdhc_2 {
	status = "ok";
};
